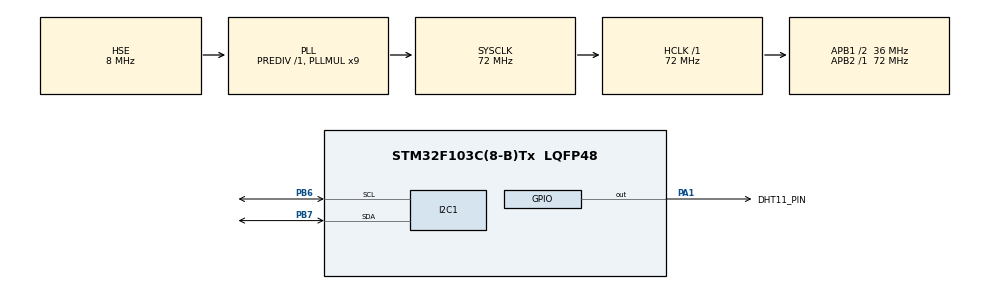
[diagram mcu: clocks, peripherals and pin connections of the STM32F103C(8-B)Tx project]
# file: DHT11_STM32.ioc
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Mcu.Family=STM32F1
Mcu.Name=STM32F103C(8-B)Tx
Mcu.Package=LQFP48
NVIC.PriorityGroup=NVIC_PRIORITYGROUP_4
PA1.GPIO_Label=DHT11_PIN
PA1.Signal=GPIO_Output
PA13.Mode=Serial_Wire
PA13.Signal=SYS_JTMS-SWDIO
PA14.Mode=Serial_Wire
PA14.Signal=SYS_JTCK-SWCLK
PB6.Mode=I2C
PB6.Signal=I2C1_SCL
PB7.Mode=I2C
PB7.Signal=I2C1_SDA
PD0-OSC_IN.Mode=HSE-External-Oscillator
PD0-OSC_IN.Signal=RCC_OSC_IN
PD1-OSC_OUT.Mode=HSE-External-Oscillator
PD1-OSC_OUT.Signal=RCC_OSC_OUT
ProjectManager.HeapSize=0x200
ProjectManager.StackSize=0x400
ProjectManager.TargetToolchain=MDK-ARM V5.32
RCC.AHBFreq_Value=72000000
RCC.APB1CLKDivider=RCC_HCLK_DIV2
RCC.APB1Freq_Value=36000000
RCC.APB1TimFreq_Value=72000000
RCC.APB2Freq_Value=72000000
RCC.APB2TimFreq_Value=72000000
RCC.HCLKFreq_Value=72000000
RCC.PLLMUL=RCC_PLL_MUL9
RCC.PLLSourceVirtual=RCC_PLLSOURCE_HSE
RCC.SYSCLKFreq_VALUE=72000000
RCC.SYSCLKSource=RCC_SYSCLKSOURCE_PLLCLK
RCC.USBFreq_Value=72000000
TIM2.Prescaler=71
VP_TIM2_VS_ClockSourceINT.Mode=Internal
board=custom

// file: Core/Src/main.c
/* USER CODE BEGIN Header */
/**
  ******************************************************************************
  * @file           : main.c
  * @brief          : Main program body
  ******************************************************************************
  * @attention
  *
  * Copyright (c) 2026 STMicroelectronics.
  * All rights reserved.
  *
  * This software is licensed under terms that can be found in the LICENSE file
  * in the root directory of this software component.
  * If no LICENSE file comes with this software, it is provided AS-IS.
  *
  ******************************************************************************
  */
/* USER CODE END Header */
#include "main.h"

/* USER CODE BEGIN Includes */
#include "dht11.h"
#include "i2c-lcd.h"
#include <stdio.h> // Ðe dùng hàm sprintf ghép chuoi hien thi
/* USER CODE END Includes */

I2C_HandleTypeDef hi2c1;

TIM_HandleTypeDef htim2;

/* USER CODE BEGIN PV */
// Tao mang 8 byte ve bieu tuong (° C) cho CGRAM
uint8_t Custom_Degree[8] = {
    0x06,
    0x09,
    0x09,
    0x06,
    0x00,
    0x00,
    0x00,
    0x00
};

uint8_t nhiet_do = 0, do_am = 0;
uint8_t temp_min = 99, temp_max = 0;
uint8_t hum_min = 99, hum_max = 0;

uint32_t last_page_change = 0;
uint8_t display_page = 0; // 0: Trang luc dau , 1: Trang Min/Max
char lcd_buff[20];
/* USER CODE END PV */

void SystemClock_Config(void);
static void MX_GPIO_Init(void);
static void MX_TIM2_Init(void);
static void MX_I2C1_Init(void);

int main(void)
{

  /* MCU Configuration--------------------------------------------------------*/

  /* Reset of all peripherals, Initializes the Flash interface and the Systick. */
  HAL_Init();

  /* Configure the system clock */
  SystemClock_Config();

  /* Initialize all configured peripherals */
  MX_GPIO_Init();
  MX_TIM2_Init();
  MX_I2C1_Init();
  /* USER CODE BEGIN 2 */
HAL_TIM_Base_Start(&htim2);

lcd_init();
lcd_clear();
lcd_create_custom_char(0, Custom_Degree);
  /* USER CODE END 2 */
// Hien thi màn hình chào m?ng
  lcd_put_cur(0, 0);
  lcd_send_string("TRAM DO NHIET DO");
  lcd_put_cur(1, 0);
  lcd_send_string("BAT DAU KHOI DONG");
  HAL_Delay(1500);
  lcd_clear();
  /* Infinite loop */
  /* USER CODE BEGIN WHILE */
  while (1)
  {
		// 1. Ðoc du lieu DHT11
      if (DHT11_Read(&nhiet_do, &do_am) == 0) { // 0 là thành công OK

          // Cap nhat giá tri Min / Max Nhiet do va Ðo am
          if (nhiet_do < temp_min) temp_min = nhiet_do;
          if (nhiet_do > temp_max) temp_max = nhiet_do;
          if (do_am < hum_min) hum_min = do_am;
          if (do_am > hum_max) hum_max = do_am;

          // 2. Chuyen trang sau moi 5 GIÂY
          if (HAL_GetTick() - last_page_change > 5000) {
              display_page = !display_page; // Ðoi trang 0 <-> 1
              last_page_change = HAL_GetTick();
              lcd_clear();
          }

          //  Trang 0: Hien thi Nhiet do & Ðo ?am thoi gian thuc ---
          if (display_page == 0) {
              // Dòng 1: Temp: XX°C
              lcd_put_cur(0, 0);
              sprintf(lcd_buff, "Nhiet do: %2d.0", nhiet_do);
              lcd_send_string(lcd_buff);
              lcd_send_data(0); // In ký tu (°C)
              lcd_send_string("C");

              // Dòng 2: Humi: XX%
              lcd_put_cur(1, 0);
              sprintf(lcd_buff, "Do am   : %2d.0%% ", do_am);
              lcd_send_string(lcd_buff);
          }
          // --- TRANG 1: Hien thi giá tri MIN / MAX ---
          else {
              // Dòng 1: T: Min-Max °C
              lcd_put_cur(0, 0);
              sprintf(lcd_buff, "T:%2d- %2d", temp_min, temp_max);
              lcd_send_string(lcd_buff);
              lcd_send_data(0);
              lcd_send_string("C ");

              // Dòng 2: H: Min-Max %
              lcd_put_cur(1, 0);
              sprintf(lcd_buff, "H:%2d- %2d %% ", hum_min, hum_max);
              lcd_send_string(lcd_buff);
          }

      } else {
          // Báo loi rút dây / Timeout / Sai Checksum
          lcd_put_cur(0, 0);
          lcd_send_string("LOI CAM BIEN!  ");
          lcd_put_cur(1, 0);
          lcd_send_string("KIEM TRA DAY... ");
      }

      HAL_Delay(1000); // Cap nhau sau moi 1 giây

    /* USER CODE END WHILE */
  }
}

void SystemClock_Config(void)
{
  RCC_OscInitTypeDef RCC_OscInitStruct = {0};
  RCC_ClkInitTypeDef RCC_ClkInitStruct = {0};

  /** Initializes the RCC Oscillators according to the specified parameters
  * in the RCC_OscInitTypeDef structure.
  */
  RCC_OscInitStruct.OscillatorType = RCC_OSCILLATORTYPE_HSE;
  RCC_OscInitStruct.HSEState = RCC_HSE_ON;
  RCC_OscInitStruct.HSEPredivValue = RCC_HSE_PREDIV_DIV1;
  RCC_OscInitStruct.HSIState = RCC_HSI_ON;
  RCC_OscInitStruct.PLL.PLLState = RCC_PLL_ON;
  RCC_OscInitStruct.PLL.PLLSource = RCC_PLLSOURCE_HSE;
  RCC_OscInitStruct.PLL.PLLMUL = RCC_PLL_MUL9;
  if (HAL_RCC_OscConfig(&RCC_OscInitStruct) != HAL_OK)
  {
    Error_Handler();
  }

  /** Initializes the CPU, AHB and APB buses clocks
  */
  RCC_ClkInitStruct.ClockType = RCC_CLOCKTYPE_HCLK|RCC_CLOCKTYPE_SYSCLK
                              |RCC_CLOCKTYPE_PCLK1|RCC_CLOCKTYPE_PCLK2;
  RCC_ClkInitStruct.SYSCLKSource = RCC_SYSCLKSOURCE_PLLCLK;
  RCC_ClkInitStruct.AHBCLKDivider = RCC_SYSCLK_DIV1;
  RCC_ClkInitStruct.APB1CLKDivider = RCC_HCLK_DIV2;
  RCC_ClkInitStruct.APB2CLKDivider = RCC_HCLK_DIV1;

  if (HAL_RCC_ClockConfig(&RCC_ClkInitStruct, FLASH_LATENCY_2) != HAL_OK)
  {
    Error_Handler();
  }
}

static void MX_I2C1_Init(void)
{

  hi2c1.Instance = I2C1;
  hi2c1.Init.ClockSpeed = 100000;
  hi2c1.Init.DutyCycle = I2C_DUTYCYCLE_2;
  hi2c1.Init.OwnAddress1 = 0;
  hi2c1.Init.AddressingMode = I2C_ADDRESSINGMODE_7BIT;
  hi2c1.Init.DualAddressMode = I2C_DUALADDRESS_DISABLE;
  hi2c1.Init.OwnAddress2 = 0;
  hi2c1.Init.GeneralCallMode = I2C_GENERALCALL_DISABLE;
  hi2c1.Init.NoStretchMode = I2C_NOSTRETCH_DISABLE;
  if (HAL_I2C_Init(&hi2c1) != HAL_OK)
  {
    Error_Handler();
  }

}

static void MX_TIM2_Init(void)
{

  TIM_ClockConfigTypeDef sClockSourceConfig = {0};
  TIM_MasterConfigTypeDef sMasterConfig = {0};

  htim2.Instance = TIM2;
  htim2.Init.Prescaler = 71;
  htim2.Init.CounterMode = TIM_COUNTERMODE_UP;
  htim2.Init.Period = 65535;
  htim2.Init.ClockDivision = TIM_CLOCKDIVISION_DIV1;
  htim2.Init.AutoReloadPreload = TIM_AUTORELOAD_PRELOAD_DISABLE;
  if (HAL_TIM_Base_Init(&htim2) != HAL_OK)
  {
    Error_Handler();
  }
  sClockSourceConfig.ClockSource = TIM_CLOCKSOURCE_INTERNAL;
  if (HAL_TIM_ConfigClockSource(&htim2, &sClockSourceConfig) != HAL_OK)
  {
    Error_Handler();
  }
  sMasterConfig.MasterOutputTrigger = TIM_TRGO_RESET;
  sMasterConfig.MasterSlaveMode = TIM_MASTERSLAVEMODE_DISABLE;
  if (HAL_TIMEx_MasterConfigSynchronization(&htim2, &sMasterConfig) != HAL_OK)
  {
    Error_Handler();
  }

}

static void MX_GPIO_Init(void)
{
  GPIO_InitTypeDef GPIO_InitStruct = {0};

  /* GPIO Ports Clock Enable */
  __HAL_RCC_GPIOD_CLK_ENABLE();
  __HAL_RCC_GPIOA_CLK_ENABLE();
  __HAL_RCC_GPIOB_CLK_ENABLE();

  /*Configure GPIO pin Output Level */
  HAL_GPIO_WritePin(DHT11_PIN_GPIO_Port, DHT11_PIN_Pin, GPIO_PIN_RESET);

  /*Configure GPIO pin : DHT11_PIN_Pin */
  GPIO_InitStruct.Pin = DHT11_PIN_Pin;
  GPIO_InitStruct.Mode = GPIO_MODE_OUTPUT_PP;
  GPIO_InitStruct.Pull = GPIO_NOPULL;
  GPIO_InitStruct.Speed = GPIO_SPEED_FREQ_LOW;
  HAL_GPIO_Init(DHT11_PIN_GPIO_Port, &GPIO_InitStruct);

}

void Error_Handler(void)
{
  __disable_irq();
  while (1)
  {
  }
}
